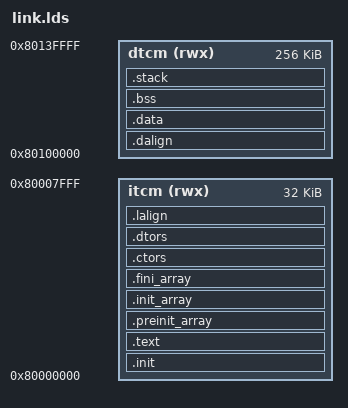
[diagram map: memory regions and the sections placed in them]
OUTPUT_ARCH( "riscv" )
ENTRY(_start)


MEMORY
{
  itcm (rwx) : ORIGIN = 0x80000000, LENGTH = 32K
  dtcm (rwx) : ORIGIN = 0x80100000, LENGTH = 256K
}


SECTIONS
{
   __stack_size = DEFINED(__stack_size) ? __stack_size : 16K;

  .init           :
  {
    KEEP (*(SORT_NONE(.init)))
  } >itcm AT>itcm 

  .text           :
  {
    *(.text.unlikely .text.unlikely.*)
    *(.text.startup .text.startup.*)
    *(.text .text.*)
    *(.gnu.linkonce.t.*)

    /* section information for utest */
    . = ALIGN(4);
    PROVIDE(__rt_utest_tc_tab_start = .);
    KEEP(*(UtestTcTab))
    PROVIDE(__rt_utest_tc_tab_end = .);

    /* section information for finsh shell */
    . = ALIGN(4);
    __fsymtab_start = .;
    KEEP(*(FSymTab))
    __fsymtab_end = .;
    . = ALIGN(4);
    __vsymtab_start = .;
    KEEP(*(VSymTab))
    __vsymtab_end = .;
    . = ALIGN(4);

    /* section information for initial. */
    . = ALIGN(4);
    __rt_init_start = .;
    KEEP(*(SORT(.rti_fn*)))
    __rt_init_end = .;
    . = ALIGN(4);

    /* section information for modules */
    . = ALIGN(4);
    __rtmsymtab_start = .;
    KEEP(*(RTMSymTab))
    __rtmsymtab_end = .;

  } >itcm AT>itcm 

  . = ALIGN(4);

  PROVIDE (__etext = .);
  PROVIDE (_etext = .);
  PROVIDE (etext = .);

  .preinit_array  :
  {
    PROVIDE_HIDDEN (__preinit_array_start = .);
    KEEP (*(.preinit_array))
    PROVIDE_HIDDEN (__preinit_array_end = .);
  } >itcm AT>itcm 

  .init_array     :
  {
    PROVIDE_HIDDEN (__init_array_start = .);
    KEEP (*(SORT_BY_INIT_PRIORITY(.init_array.*) SORT_BY_INIT_PRIORITY(.ctors.*)))
    KEEP (*(.init_array EXCLUDE_FILE (*crtbegin.o *crtbegin?.o *crtend.o *crtend?.o ) .ctors))
    PROVIDE_HIDDEN (__init_array_end = .);
  } >itcm AT>itcm 

  .fini_array     :
  {
    PROVIDE_HIDDEN (__fini_array_start = .);
    KEEP (*(SORT_BY_INIT_PRIORITY(.fini_array.*) SORT_BY_INIT_PRIORITY(.dtors.*)))
    KEEP (*(.fini_array EXCLUDE_FILE (*crtbegin.o *crtbegin?.o *crtend.o *crtend?.o ) .dtors))
    PROVIDE_HIDDEN (__fini_array_end = .);
  } >itcm AT>itcm 

  .ctors          :
  {
    KEEP (*crtbegin.o(.ctors))
    KEEP (*crtbegin?.o(.ctors))
    KEEP (*(EXCLUDE_FILE (*crtend.o *crtend?.o ) .ctors))
    KEEP (*(SORT(.ctors.*)))
    KEEP (*(.ctors))
  } >itcm AT>itcm 

  .dtors          :
  {
    KEEP (*crtbegin.o(.dtors))
    KEEP (*crtbegin?.o(.dtors))
    KEEP (*(EXCLUDE_FILE (*crtend.o *crtend?.o ) .dtors))
    KEEP (*(SORT(.dtors.*)))
    KEEP (*(.dtors))
  } >itcm AT>itcm 

  .lalign         :
  {
    . = ALIGN(4);
    PROVIDE( _data_lma = . );
  } >itcm AT>itcm 

  .dalign         :
  {
    . = ALIGN(4);
    PROVIDE( _data = . );
  } >dtcm

  .data          :
  {
    *(.rdata)
    *(.rodata .rodata.*)
    *(.gnu.linkonce.r.*)
    *(.data .data.*)
    *(.gnu.linkonce.d.*)
    . = ALIGN(8);
    PROVIDE( __global_pointer$ = . + 0x800 );
    *(.sdata .sdata.*)
    *(.gnu.linkonce.s.*)
    . = ALIGN(8);
    *(.srodata.cst16)
    *(.srodata.cst8)
    *(.srodata.cst4)
    *(.srodata.cst2)
    *(.srodata .srodata.*)
  } >dtcm

  . = ALIGN(4);
  PROVIDE( _edata = . );
  PROVIDE( edata = . );

  PROVIDE( _fbss = . );
  PROVIDE( __bss_start = . );
  .bss            :
  {
    *(.sbss*)
    *(.gnu.linkonce.sb.*)
    *(.bss .bss.*)
    *(.gnu.linkonce.b.*)
    *(COMMON)
    . = ALIGN(4);
  } >dtcm AT>dtcm 

  . = ALIGN(8);
  PROVIDE( _end = . );
  PROVIDE( end = . );

  /* Reserve space for heap before stack */
  . = . + 16K;  /* Reserve 16KB for heap */
  PROVIDE( _heap_end = . );

  .stack :
  {
    . = . + __stack_size;
    PROVIDE( _sp = . );
    __stack_top = .;
    PROVIDE( __rt_rvstack = . );
  } >dtcm AT>dtcm

}
